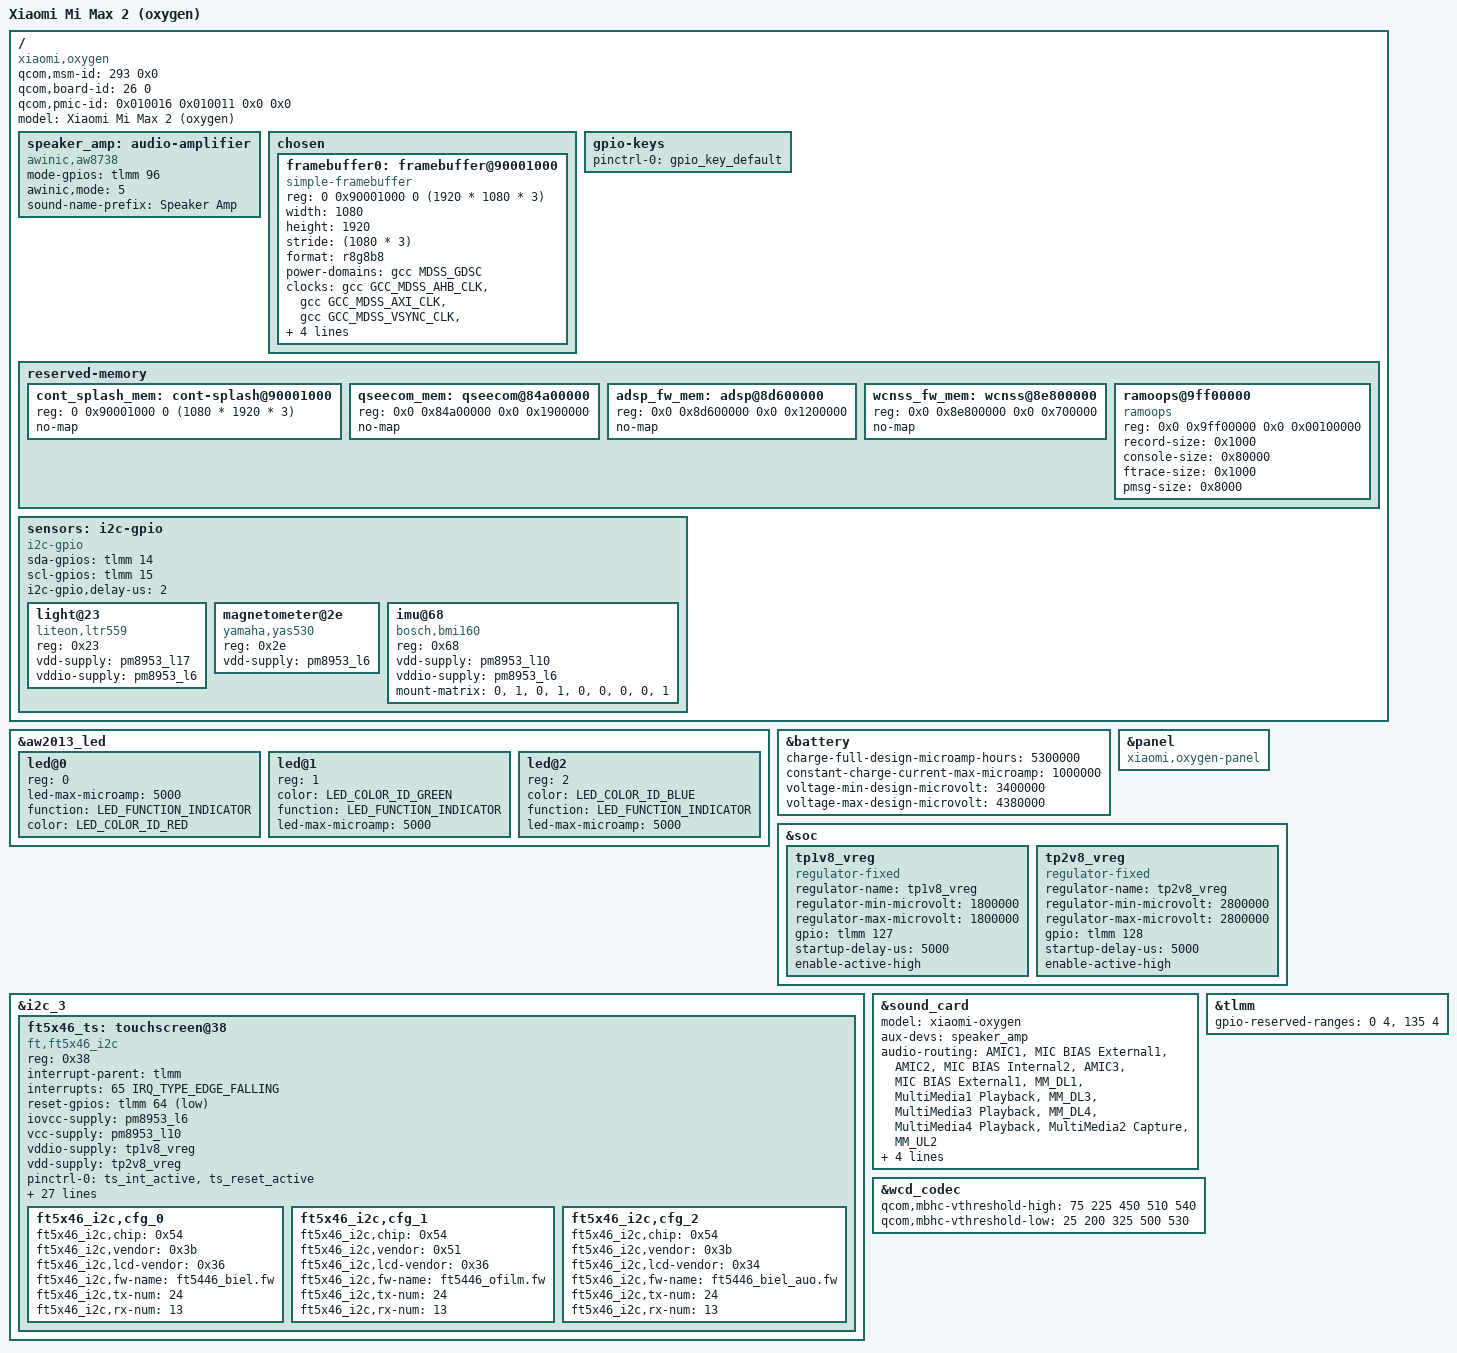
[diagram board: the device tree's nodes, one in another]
// SPDX-License-Identifier: BSD-3-Clause
/dts-v1/;

#include "msm8953-xiaomi-common.dtsi"
#include <dt-bindings/input/atmel-maxtouch.h>

/delete-node/ &adsp_fw_mem;
/delete-node/ &qseecom_mem;
/delete-node/ &wcnss_fw_mem;
/ {
	qcom,msm-id = <293 0x0>;
	qcom,board-id = <26 0>;
	qcom,pmic-id = <0x010016 0x010011 0x0 0x0>;

	model = "Xiaomi Mi Max 2 (oxygen)";
	compatible = "xiaomi,oxygen", "qcom,msm8953";

	speaker_amp: audio-amplifier {
		compatible = "awinic,aw8738";
		mode-gpios = <&tlmm 96 GPIO_ACTIVE_HIGH>;
		awinic,mode = <5>;
		sound-name-prefix = "Speaker Amp";
	};

	chosen {
		#address-cells = <2>;
		#size-cells = <2>;
		ranges;

		framebuffer0: framebuffer@90001000 {
			compatible = "simple-framebuffer";
			reg = <0 0x90001000 0 (1920 * 1080 * 3)>;

			width = <1080>;
			height = <1920>;
			stride = <(1080 * 3)>;
			format = "r8g8b8";

			power-domains = <&gcc MDSS_GDSC>;

			clocks = <&gcc GCC_MDSS_AHB_CLK>,
				 <&gcc GCC_MDSS_AXI_CLK>,
				 <&gcc GCC_MDSS_VSYNC_CLK>,
				 <&gcc GCC_MDSS_MDP_CLK>,
				 <&gcc GCC_MDSS_BYTE0_CLK>,
				 <&gcc GCC_MDSS_PCLK0_CLK>,
				 <&gcc GCC_MDSS_ESC0_CLK>;
		};
	};

	gpio-keys {
		pinctrl-0 = <&gpio_key_default>;
		pinctrl-names = "default";
	};

	reserved-memory {
		cont_splash_mem: cont-splash@90001000 {
			reg = <0 0x90001000 0 (1080 * 1920 * 3)>;
			no-map;
		};

		qseecom_mem: qseecom@84a00000 {
			reg = <0x0 0x84a00000 0x0 0x1900000>;
			no-map;
		};

		adsp_fw_mem: adsp@8d600000 {
			reg = <0x0 0x8d600000 0x0 0x1200000>;
			no-map;
		};

		wcnss_fw_mem: wcnss@8e800000 {
			reg = <0x0 0x8e800000 0x0 0x700000>;
			no-map;
		};
		ramoops@9ff00000 {
			compatible = "ramoops";
			reg = <0x0 0x9ff00000 0x0 0x00100000>;
			record-size = <0x1000>;
			console-size = <0x80000>;
			ftrace-size = <0x1000>;
			pmsg-size = <0x8000>;
		};
	};

	sensors: i2c-gpio {
		compatible = "i2c-gpio";
		sda-gpios = <&tlmm 14 (GPIO_ACTIVE_HIGH|GPIO_OPEN_DRAIN)>;
		scl-gpios = <&tlmm 15 (GPIO_ACTIVE_HIGH|GPIO_OPEN_DRAIN)>;
		i2c-gpio,delay-us = <2>;        /* ~100 kHz */
		#address-cells = <1>;
		#size-cells = <0>;

		light@23 {
			compatible = "liteon,ltr559";
			reg = <0x23>;

			vdd-supply = <&pm8953_l17>;
			vddio-supply = <&pm8953_l6>;
		};

		magnetometer@2e {
			compatible = "yamaha,yas530";
			reg = <0x2e>;

			vdd-supply = <&pm8953_l6>;
		};

		imu@68 {
			compatible = "bosch,bmi160";
			reg = <0x68>;

			vdd-supply = <&pm8953_l10>;
			vddio-supply = <&pm8953_l6>;

			mount-matrix = "0", "1", "0",
					"1", "0", "0",
					"0", "0", "1";
		};
	};
};

&aw2013_led {
	status = "okay";

	led@0 {
		reg = <0>;
		led-max-microamp = <5000>;
		function = LED_FUNCTION_INDICATOR;
		color = <LED_COLOR_ID_RED>;
	};

	led@1 {
		reg = <1>;
		color = <LED_COLOR_ID_GREEN>;
		function = LED_FUNCTION_INDICATOR;
		led-max-microamp = <5000>;
	};

	led@2 {
		reg = <2>;
		color = <LED_COLOR_ID_BLUE>;
		function = LED_FUNCTION_INDICATOR;
		led-max-microamp = <5000>;
	};
};

&battery {
	charge-full-design-microamp-hours = <5300000>;
	constant-charge-current-max-microamp = <1000000>;
	voltage-min-design-microvolt = <3400000>;
	voltage-max-design-microvolt = <4380000>;
};


&panel {
	compatible = "xiaomi,oxygen-panel"; 
};

&soc {
	tp1v8_vreg: tp1v8_vreg {
		compatible = "regulator-fixed";
		regulator-name = "tp1v8_vreg";
		regulator-min-microvolt = <1800000>;
		regulator-max-microvolt = <1800000>;
		gpio = <&tlmm 127 0>;
		startup-delay-us = <5000>;
		enable-active-high;
	};

	tp2v8_vreg: tp2v8_vreg {
		compatible = "regulator-fixed";
		regulator-name = "tp2v8_vreg";
		regulator-min-microvolt = <2800000>;
		regulator-max-microvolt = <2800000>;
		gpio = <&tlmm  128 0>;
		startup-delay-us = <5000>;
		enable-active-high;
	};

};
&i2c_3 {
	ft5x46_ts: touchscreen@38 {
		compatible = "ft,ft5x46_i2c";
		status = "okay";
		reg = <0x38>;

		interrupt-parent = <&tlmm>;
		interrupts = <65 IRQ_TYPE_EDGE_FALLING>;
		reset-gpios = <&tlmm 64 GPIO_ACTIVE_LOW>;
		iovcc-supply = <&pm8953_l6>;
		vcc-supply = <&pm8953_l10>;
		status = "okay";
		vddio-supply = <&tp1v8_vreg>;
		vdd-supply = <&tp2v8_vreg>;
		/* pins used by touchscreen */
		pinctrl-names = "pmx_ts_active","pmx_ts_suspend";
		pinctrl-0 = <&ts_int_active &ts_reset_active>;
		pinctrl-1 = <&ts_int_suspend &ts_reset_suspend>;
		ft5x46_i2c,i2c-pull-up;
		ft5x46_i2c,irqflags = <0x2008>;
		ft5x46_i2c,x-max = <1080>;
		ft5x46_i2c,y-max = <1920>;
		ft5x46_i2c,z-max = <255>;
		ft5x46_i2c,w-max = <200>;
		ft5x46_i2c,reset-gpio = <&tlmm 64 0x00>;
		ft5x46_i2c,irq-gpio = <&tlmm 65 0x2008>;
		ft5x46_i2c,landing-jiffies = <1000>;
		ft5x46_i2c,landing-threshold = <16>;
		ft5x46_i2c,staying-threshold = <8>;
		ft5x46_i2c,raw-min = <7000>;
		ft5x46_i2c,raw-max = <10000>;
		ft5x46_i2c,has-key;
		ft5x46_i2c,key-rx1 = <4>;
		ft5x46_i2c,key-rx2 = <8>;
		ft5x46_i2c,key-rx3 = <12>;
		ft5x46_i2c,open-min = <4000>;
		ft5x46_i2c,imin-cc = <500>;
		ft5x46_i2c,imin-cg = <500>;
		ft5x46_i2c,fw-delay-55-ms = <2>;
		ft5x46_i2c,fw-delay-aa-ms = <2>;
		ft5x46_i2c,fw-upgrade-id1 = <0x54>;
		ft5x46_i2c,fw-upgrade-id2 = <0x2C>;
		ft5x46_i2c,fw-delay-readid-ms = <20>;
		ft5x46_i2c,firmware-array-size = <3>;
		ft5x46_i2c,cfg_0 {
			ft5x46_i2c,chip = <0x54>;
			ft5x46_i2c,vendor = <0x3b>;
			ft5x46_i2c,lcd-vendor = <0x36>;
			ft5x46_i2c,fw-name = "ft5446_biel.fw";
			ft5x46_i2c,tx-num = <24>;
			ft5x46_i2c,rx-num = <13>;
		};
		ft5x46_i2c,cfg_1 {
			ft5x46_i2c,chip = <0x54>;
			ft5x46_i2c,vendor = <0x51>;
			ft5x46_i2c,lcd-vendor = <0x36>;
			ft5x46_i2c,fw-name = "ft5446_ofilm.fw";
			ft5x46_i2c,tx-num = <24>;
			ft5x46_i2c,rx-num = <13>;
		};
		ft5x46_i2c,cfg_2 {
			ft5x46_i2c,chip = <0x54>;
			ft5x46_i2c,vendor = <0x3b>;
			ft5x46_i2c,lcd-vendor = <0x34>;
			ft5x46_i2c,fw-name = "ft5446_biel_auo.fw";
			ft5x46_i2c,tx-num = <24>;
			ft5x46_i2c,rx-num = <13>;
		};	
	};
};




&sound_card {
	model = "xiaomi-oxygen";

	aux-devs = <&speaker_amp>;
	audio-routing =
		"AMIC1", "MIC BIAS External1",
		"AMIC2", "MIC BIAS Internal2",
		"AMIC3", "MIC BIAS External1",
		"MM_DL1", "MultiMedia1 Playback",
		"MM_DL3", "MultiMedia3 Playback",
		"MM_DL4", "MultiMedia4 Playback",
		"MultiMedia2 Capture", "MM_UL2";

	pinctrl-0 = <&cdc_pdm_lines_act &cdc_pdm_lines_2_act &cdc_pdm_comp_lines_act>;
	pinctrl-1 = <&cdc_pdm_lines_sus &cdc_pdm_lines_2_sus &cdc_pdm_comp_lines_sus>;
	pinctrl-names = "default", "sleep";

	status = "okay";
};

&tlmm {
	gpio-reserved-ranges = <0 4>, <135 4>;
};

&wcd_codec {
	/delete-property/ qcom,gnd-jack-type-normally-open;
	qcom,mbhc-vthreshold-high = <75 225 450 510 540>;
	qcom,mbhc-vthreshold-low = <25 200 325 500 530>;
};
